AUTOSAR XML (schema 4-2-1)
package /ComponentTypes
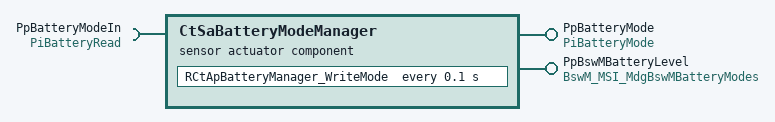
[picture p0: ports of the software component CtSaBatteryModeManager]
  sensor actuator sw component type CtSaBatteryModeManager
    provide port PpBatteryMode: mode-switch-sender-com-spec{enhanced-mode-api=false, mode-group=BatteryModes, queue-length=1}, provided-interface=PiBatteryMode
    provide port PpBswMBatteryLevel: mode-switch-sender-com-spec{enhanced-mode-api=false, mode-group=BswM_MDGP_MdgBswMBatteryModes, queue-length=1}, provided-interface=BswM_MSI_MdgBswMBatteryModes
    require port PpBatteryModeIn: required-interface=PiBatteryRead
    behavior CtSaBatteryModeManager_InternalBehavior: data-type-mapping=ApMappingSet
      timing event TMT_RCtApBatteryManager_WriteMode: start-on-event=RCtApBatteryManager_WriteMode, period=0.1
      runnable RCtApBatteryManager_WriteMode: symbol=RCtApBatteryManager
        mode switch point SWITCH_PpBatteryMode_BatteryModes: mode-group=PpBatteryMode.BatteryModes
        mode switch point SWITCH_PpBswMBatteryLevel_BswM_MDGP_MdgBswMBatteryModes: mode-group=PpBswMBatteryLevel.BswM_MDGP_MdgBswMBatteryModes
        sync call SC_PpBatteryModeIn_ReadChannel: operation=PpBatteryModeIn.ReadChannel, timeout=0
  swc implementation CtSaBatteryModeManager_Implementation: behavior=CtSaBatteryModeManager_InternalBehavior
    code-descriptors:
      code Default: artifact-descriptors=autosar-engineering-object={short-label=Default, category=SWSRC}
